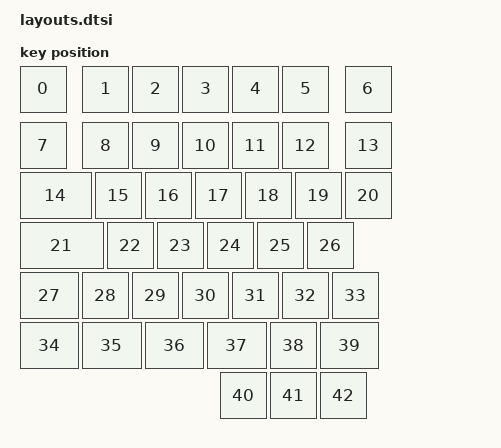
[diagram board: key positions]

#include <physical_layouts.dtsi>
/ {
    physical_layout0: physical_layout0 {
        compatible = "zmk,physical-layout";
        display-name = "Layout";
        keys
            = <&key_physical_attrs 100 100 (-50) 0 0 0 0>
			,<&key_physical_attrs 100 100 75 0 0 0 0>
			,<&key_physical_attrs 100 100 175 0 0 0 0>
			,<&key_physical_attrs 100 100 275 0 0 0 0>
			,<&key_physical_attrs 100 100 375 0 0 0 0>
			,<&key_physical_attrs 100 100 475 0 0 0 0>
			,<&key_physical_attrs 100 100 600 0 0 0 0>
			,<&key_physical_attrs 100 100 (-50) 113 0 0 0>
			,<&key_physical_attrs 100 100 75 113 0 0 0>
			,<&key_physical_attrs 100 100 175 113 0 0 0>
			,<&key_physical_attrs 100 100 275 113 0 0 0>
			,<&key_physical_attrs 100 100 375 113 0 0 0>
			,<&key_physical_attrs 100 100 475 113 0 0 0>
			,<&key_physical_attrs 100 100 600 113 0 0 0>
			,<&key_physical_attrs 150 100 (-50) 213 0 0 0>
			,<&key_physical_attrs 100 100 100 213 0 0 0>
			,<&key_physical_attrs 100 100 200 213 0 0 0>
			,<&key_physical_attrs 100 100 300 213 0 0 0>
			,<&key_physical_attrs 100 100 400 213 0 0 0>
			,<&key_physical_attrs 100 100 500 213 0 0 0>
			,<&key_physical_attrs 100 100 600 213 0 0 0>
			,<&key_physical_attrs 175 100 (-50) 313 0 0 0>
			,<&key_physical_attrs 100 100 125 313 0 0 0>
			,<&key_physical_attrs 100 100 225 313 0 0 0>
			,<&key_physical_attrs 100 100 325 313 0 0 0>
			,<&key_physical_attrs 100 100 425 313 0 0 0>
			,<&key_physical_attrs 100 100 525 313 0 0 0>
			,<&key_physical_attrs 125 100 (-50) 413 0 0 0>
			,<&key_physical_attrs 100 100 75 413 0 0 0>
			,<&key_physical_attrs 100 100 175 413 0 0 0>
			,<&key_physical_attrs 100 100 275 413 0 0 0>
			,<&key_physical_attrs 100 100 375 413 0 0 0>
			,<&key_physical_attrs 100 100 475 413 0 0 0>
			,<&key_physical_attrs 100 100 575 413 0 0 0>
			,<&key_physical_attrs 125 100 (-50) 513 0 0 0>
			,<&key_physical_attrs 125 100 75 513 0 0 0>
			,<&key_physical_attrs 125 100 200 513 0 0 0>
			,<&key_physical_attrs 125 100 325 513 0 0 0>
			,<&key_physical_attrs 100 100 450 513 0 0 0>
			,<&key_physical_attrs 125 100 550 513 0 0 0>
			,<&key_physical_attrs 100 100 350 613 0 0 0>
			,<&key_physical_attrs 100 100 450 613 0 0 0>
			,<&key_physical_attrs 100 100 550 613 0 0 0>
            ;
    };
};
    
